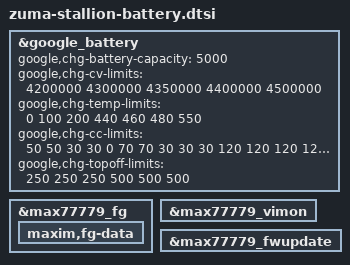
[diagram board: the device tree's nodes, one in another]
// SPDX-License-Identifier: GPL-2.0-only
/*
 * Battery device tree entries specific to stallion
 *
 * Copyright 2024 Google LLC
 *
 */

&google_battery {
	google,chg-battery-capacity = <5000>;

	google,chg-cv-limits = <4200000 4300000 4350000 4400000 4500000>;
	google,chg-temp-limits = <0 100 200 440 460 480 550>;
	google,chg-cc-limits = <
		 50   50   30   30    0
		 70   70   30   30   30
		120  120  120  120   50
		120  120  120  120   50
		 50   50    0    0    0
		 30    0    0    0    0
	>;
	google,chg-topoff-limits = <250 250 250 500 500 500>;
};

&max77779_fg {
	maxim,fg-data {
		#include "zuma-stallion-battery-data.dtsi"
	};
};

&max77779_vimon {
	status = "okay";
};

&max77779_fwupdate {
	status = "okay";
};
